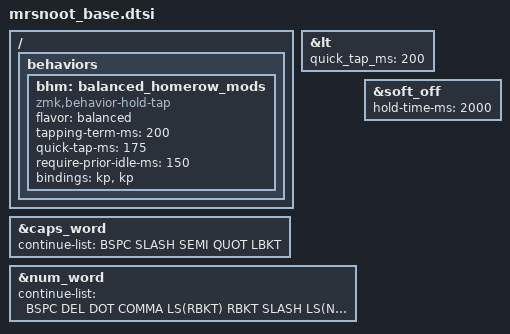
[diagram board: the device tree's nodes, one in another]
#include <behaviors.dtsi>
#include <dt-bindings/zmk/bt.h>
#include <dt-bindings/zmk/keys.h>
#include <dt-bindings/zmk/mouse.h>
#include <behaviors/num_word.dtsi>

#define BT(n) BT_SEL n

// Layers
#define SON_L 0
#define NAV_L 1
#define MS_L  2
#define NUM_L 3
#define SYM_L 4
#define ADJ_L 5

// Default
#define _______ &trans
#define XXXXXXX &none

// Diverse Keycodes
#define NP_XMLL &kp LC(LS(LA(L)))
#define NP_XMLF &kp LC(LS(LA(B)))
#define GUI_SS  &bhm LGUI MINUS
#define MICMUTE &kp LC(LS(M))
#define LT_MS_C &lt MS_L C
#define LT_CMB2 &bhm LCTRL &mkp MB2
#define ALT_F5  &kp LA(F5)
#define TG_MS_L &tog MS_L
#define DE_EXLM &kp LS(N1)
#define DE_QUES &kp LS(MINUS)
#define DE_DEG  &kp LS(GRAVE)
#define DE_LCBR &kp RA(N7)
#define DE_SECT &kp LS(N3)
#define DE_DLR  &kp LS(N4)
#define DE_AMPR &kp LS(N6)
#define DE_RCBR &kp RA(N0)
#define DE_LPRN &kp LS(N8)
#define DE_RPRN &kp LS(N9)
#define DE_LBRC &kp RA(N8)
#define DE_RBRC &kp RA(N9)
#define DE_LABK &kp NUBS
#define DE_RABK &kp LS(NUBS)
#define DE_PIPE &kp RA(NUBS)
#define DE_CIRC &kp GRAVE
#define DE_TILD &kp RA(RBKT)
#define DE_ACUT &kp EQUAL
#define DE_GRV  &kp LS(EQUAL)

// Thumbs
#define NUM_SPC &lt NUM_L SPACE
#define NUM_ENT &lt NUM_L ENTER

// Home Row Mods
// SONNE
#define HRM_S_A &bhm LSHFT A
#define HRM_S_I &bhm LALT I
#define HRM_S_E &bhm LCTRL E
#define HRM_S_S &lt NAV_L S
#define HRM_S_H &lt SYM_L H
#define HRM_S_T &bhm LCTRL T
#define HRM_S_N &bhm LALT N
#define HRM_S_R &bhm RSHFT R

// NUM
#define NF_F8 &bhm LSHFT F8
#define NF_F7 &bhm LALT F7
#define NF_F6 &bhm LCTRL F6
#define NF_F5 &bhm LGUI F5
#define NF_4 &bhm LGUI N4
#define NF_5 &bhm LCTRL N5
#define NF_6 &bhm LALT N6
#define NF_DOT &bhm RSHFT DOT

// Using layer taps on thumbs, having quick tap as well helps w/ repeating space/backspace
&lt { quick_tap_ms = <200>; };

&caps_word {
  // do continue on: Backspace - ä ö ü
  continue-list = <BSPC SLASH SEMI QUOT LBKT>;
};

&num_word {
   // do continue on: Backspace delete . , * + - =
  continue-list = <BSPC DEL DOT COMMA LS(RBKT) RBKT SLASH LS(N0)>;
};

&soft_off {
    hold-time-ms = <2000>; // Only turn off it the key is held for 2 seconds or longer.
};

/ {
    behaviors {
        bhm: balanced_homerow_mods {
            compatible = "zmk,behavior-hold-tap";
            flavor = "balanced";
            #binding-cells = <2>;
            tapping-term-ms = <200>;
            quick-tap-ms = <175>;
            require-prior-idle-ms = <150>;
            // hold-trigger-key-positions = <KEYS_R THUMBS>;
            // hold-trigger-on-release;   
            bindings = <&kp>, <&kp>;
        };
    };
};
